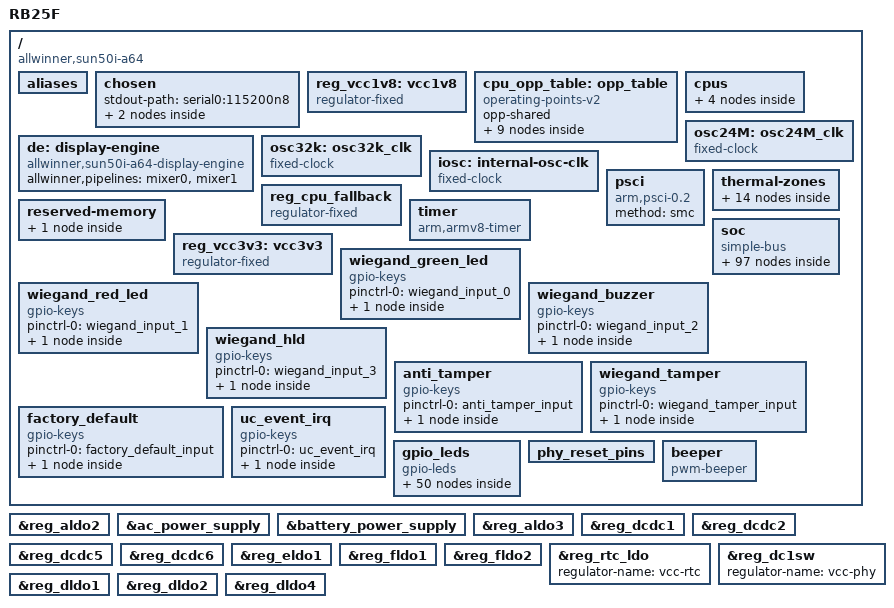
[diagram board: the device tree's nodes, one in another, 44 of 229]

/dts-v1/;

#include <dt-bindings/clock/sun8i-de2.h>
#include <dt-bindings/clock/sun50i-a64-ccu.h>
#include <dt-bindings/clock/sun8i-r-ccu.h>
#include <dt-bindings/interrupt-controller/arm-gic.h>
#include <dt-bindings/reset/sun8i-de2.h>
#include <dt-bindings/reset/sun50i-a64-ccu.h>
#include <dt-bindings/clock/sun8i-de2.h>
#include <dt-bindings/reset/sun8i-de2.h>
#include <dt-bindings/clock/sun8i-r-ccu.h>
#include <dt-bindings/reset/sun8i-r-ccu.h>
#include <dt-bindings/thermal/thermal.h>
#include <dt-bindings/gpio/gpio.h>

/ {
	model = "RB25F";
	compatible = "allwinner,sun50i-a64";
	interrupt-parent = <&gic>;
	#address-cells = <1>;
	#size-cells = <1>;

	aliases {
		serial0 = &uart0;
		ethernet0 = &emac;
		serial3 = "/soc/serial@1c28c00";
		serial2 = "/soc/serial@1c28800";
		i2c1 = "/soc/i2c@1c2b000";
	};

	chosen {
		stdout-path = "serial0:115200n8";
		#address-cells = <1>;
		#size-cells = <1>;
		ranges;

		simplefb_lcd: framebuffer-lcd {
			compatible = "allwinner,simple-framebuffer",
				     "simple-framebuffer";
			allwinner,pipeline = "mixer0-lcd0";
			clocks = <&display_clocks CLK_BUS_MIXER0>,
				 <&ccu CLK_BUS_TCON0>, <&ccu CLK_BUS_TCON0>,
				 <&display_clocks CLK_MIXER0>,
				 <&ccu CLK_TCON0>;
			status = "disabled";
		};

		simplefb_hdmi: framebuffer-hdmi {
			compatible = "allwinner,simple-framebuffer",
				     "simple-framebuffer";
			allwinner,pipeline = "mixer1-lcd1-hdmi";
			clocks = <&display_clocks CLK_BUS_MIXER1>,
				 <&ccu CLK_BUS_TCON1>, <&ccu CLK_BUS_HDMI>,
				 <&display_clocks CLK_MIXER1>,
				 <&ccu CLK_TCON1>, <&ccu CLK_HDMI>,
				 <&ccu CLK_HDMI_DDC>;
			status = "disabled";
		};
	};

	reg_vcc1v8: vcc1v8 {
		compatible = "regulator-fixed";
		regulator-name = "vcc1v8";
		regulator-min-microvolt = <1800000>;
		regulator-max-microvolt = <1800000>;
	};

	cpu_opp_table: opp_table {
		compatible = "operating-points-v2";
		opp-shared;

		opp@408000000 {
			opp-hz = /bits/ 64 <408000000>;
			opp-microvolt = <1000000 1000000 1300000>;
			clock-latency-ns = <244144>; /* 8 32k periods */
		};

		opp@648000000 {
			opp-hz = /bits/ 64 <648000000>;
			opp-microvolt = <1040000 1040000 1300000>;
			clock-latency-ns = <244144>; /* 8 32k periods */
		};

		opp@816000000 {
			opp-hz = /bits/ 64 <816000000>;
			opp-microvolt = <1080000 1080000 1300000>;
			clock-latency-ns = <244144>; /* 8 32k periods */
		};

		opp@912000000 {
		       opp-hz = /bits/ 64 <912000000>;
		       opp-microvolt = <1120000 1120000 1300000>;
		       clock-latency-ns = <244144>; /* 8 32k periods */
		};

		opp@960000000 {
		       opp-hz = /bits/ 64 <960000000>;
		       opp-microvolt = <1160000 1160000 1300000>;
		       clock-latency-ns = <244144>; /* 8 32k periods */
		};

		opp@1008000000 {
		       opp-hz = /bits/ 64 <1008000000>;
		       opp-microvolt = <1200000 1200000 1300000>;
		       clock-latency-ns = <244144>; /* 8 32k periods */
		};

		opp@1056000000 {
		       opp-hz = /bits/ 64 <1056000000>;
		       opp-microvolt = <1240000 1240000 1300000>;
		       clock-latency-ns = <244144>; /* 8 32k periods */
		};

		opp@1104000000 {
		       opp-hz = /bits/ 64 <1104000000>;
		       opp-microvolt = <1260000 1260000 1300000>;
		       clock-latency-ns = <244144>; /* 8 32k periods */
		};

		opp@1152000000 {
		       opp-hz = /bits/ 64 <1152000000>;
		       opp-microvolt = <1300000 1300000 1300000>;
		       clock-latency-ns = <244144>; /* 8 32k periods */
		};
	};

	cpus {
		#address-cells = <1>;
		#size-cells = <0>;

		cpu0: cpu@0 {
			compatible = "arm,cortex-a53", "arm,armv8";
			device_type = "cpu";
			reg = <0>;
			enable-method = "psci";
			operating-points-v2 = <&cpu_opp_table>;
			cpu-supply = <&reg_cpu_fallback>;
			#cooling-cells = <2>;
		};

		cpu1: cpu@1 {
			compatible = "arm,cortex-a53", "arm,armv8";
			device_type = "cpu";
			reg = <1>;
			enable-method = "psci";
			operating-points-v2 = <&cpu_opp_table>;
		};

		cpu2: cpu@2 {
			compatible = "arm,cortex-a53", "arm,armv8";
			device_type = "cpu";
			reg = <2>;
			enable-method = "psci";
			operating-points-v2 = <&cpu_opp_table>;
		};

		cpu3: cpu@3 {
			compatible = "arm,cortex-a53", "arm,armv8";
			device_type = "cpu";
			reg = <3>;
			enable-method = "psci";
			operating-points-v2 = <&cpu_opp_table>;
		};
	};

	de: display-engine {
		compatible = "allwinner,sun50i-a64-display-engine";
		allwinner,pipelines = <&mixer0>,
				      <&mixer1>;
		status = "disabled";
	};

	osc24M: osc24M_clk {
		#clock-cells = <0>;
		compatible = "fixed-clock";
		clock-frequency = <24000000>;
		clock-output-names = "osc24M";
	};

	osc32k: osc32k_clk {
		#clock-cells = <0>;
		compatible = "fixed-clock";
		clock-frequency = <32768>;
		clock-output-names = "osc32k";
	};

	iosc: internal-osc-clk {
		#clock-cells = <0>;
		compatible = "fixed-clock";
		clock-frequency = <16000000>;
		clock-accuracy = <300000000>;
		clock-output-names = "iosc";
	};

	psci {
		compatible = "arm,psci-0.2";
		method = "smc";
	};

	thermal-zones {
		cpu-thermal {
			/* milliseconds */
			polling-delay-passive = <250>;
			polling-delay = <1000>;
			thermal-sensors = <&ths>;

			trips {
				cpu_warm: cpu_warm {
					temperature = <65000>;
					hysteresis = <2000>;
					type = "passive";
				};

				cpu_hot_pre: cpu_hot_pre {
					temperature = <70000>;
					hysteresis = <2000>;
					type = "passive";
				};

				cpu_hot: cpu_hot {
					temperature = <75000>;
					hysteresis = <2000>;
					type = "passive";
				};

				cpu_very_hot_pre: cpu_very_hot_pre {
					temperature = <85000>;
					hysteresis = <2000>;
					type = "passive";
				};

				cpu_very_hot: cpu_very_hot {
					temperature = <90000>;
					hysteresis = <2000>;
					type = "passive";
				};

				cpu_crit: cpu_crit {
					temperature = <105000>;
					hysteresis = <2000>;
					type = "critical";
				};
			};

			cooling-maps {
				cpu_warm_limit_cpu {
					trip = <&cpu_warm>;
					cooling-device = <&cpu0 THERMAL_NO_LIMIT 2>;
				};

				cpu_hot_pre_limit_cpu {
					trip = <&cpu_hot_pre>;
					cooling-device = <&cpu0 2 3>;
				};

				cpu_hot_limit_cpu {
					trip = <&cpu_hot>;
					cooling-device = <&cpu0 3 4>;
				};

				cpu_very_hot_pre_limit_cpu {
					trip = <&cpu_very_hot>;
					cooling-device = <&cpu0 5 6>;
				};

				cpu_very_hot_limit_cpu {
					trip = <&cpu_very_hot>;
					cooling-device = <&cpu0 7 THERMAL_NO_LIMIT>;
				};
			};
		};
	};

	reg_cpu_fallback: reg_cpu_fallback  {
		compatible = "regulator-fixed";
		regulator-name = "vdd-cpux-dummy";
		regulator-min-microvolt = <1100000>;
		regulator-max-microvolt = <1100000>;
	};

	reserved-memory {
		#address-cells = <1>;
		#size-cells = <1>;
		ranges;

		cma: linux,cma {
			compatible = "shared-dma-pool";
			reusable;
			size = <0x4000000>;
			alignment = <0x2000>;
			linux,cma-default;
		};
	};
	
	timer {
		compatible = "arm,armv8-timer";
		fsl,erratum-a008585;
		interrupts = <GIC_PPI 13
			(GIC_CPU_MASK_SIMPLE(4) | IRQ_TYPE_LEVEL_HIGH)>,
			     <GIC_PPI 14
			(GIC_CPU_MASK_SIMPLE(4) | IRQ_TYPE_LEVEL_HIGH)>,
			     <GIC_PPI 11
			(GIC_CPU_MASK_SIMPLE(4) | IRQ_TYPE_LEVEL_HIGH)>,
			     <GIC_PPI 10
			(GIC_CPU_MASK_SIMPLE(4) | IRQ_TYPE_LEVEL_HIGH)>;
	};

	soc {
		compatible = "simple-bus";
		#address-cells = <1>;
		#size-cells = <1>;
		ranges;

		ths: thermal-sensor@1c25000 {
			compatible = "allwinner,sun50i-h5-ths";
			reg = <0x01c25000 0x100>;
			clocks = <&ccu CLK_BUS_THS>, <&ccu CLK_THS>;
			clock-names = "bus", "mod";
			resets = <&ccu RST_BUS_THS>;
			#thermal-sensor-cells = <0>;
			#io-channel-cells = <0>;
		};

		display_clocks: clock@1000000 {
			compatible = "allwinner,sun50i-a64-de2-clk";
			reg = <0x01000000 0x100000>;
			clocks = <&ccu CLK_DE>,
				 <&ccu CLK_BUS_DE>;
			clock-names = "mod",
				      "bus";
			resets = <&ccu RST_BUS_DE>;
			allwinner,sram = <&de2_sram 1>;
			#clock-cells = <1>;
			#reset-cells = <1>;
		};

		mixer0: mixer@1100000 {
			compatible = "allwinner,sun50i-a64-de2-mixer0";
			reg = <0x01100000 0x100000>;
			clocks = <&display_clocks CLK_MIXER0>,
				 <&display_clocks CLK_BUS_MIXER0>;
			clock-names = "mod",
				      "bus";
			resets = <&display_clocks RST_MIXER0>;
			status = "disabled";

			ports {
				#address-cells = <1>;
				#size-cells = <0>;

				mixer0_out: port@1 {
					#address-cells = <1>;
					#size-cells = <0>;
					reg = <1>;

					mixer0_out_tcon0: endpoint@0 {
						reg = <0>;
						remote-endpoint = <&tcon0_in_mixer0>;
					};

					mixer0_out_tcon1: endpoint@1 {
						reg = <1>;
						remote-endpoint = <&tcon1_in_mixer0>;
					};
				};
			};
		};

		mixer1: mixer@1200000 {
			compatible = "allwinner,sun50i-a64-de2-mixer1";
			reg = <0x01200000 0x100000>;
			clocks = <&display_clocks CLK_MIXER1>,
				 <&display_clocks CLK_BUS_MIXER1>;
			clock-names = "mod",
				      "bus";
			resets = <&display_clocks RST_MIXER1>;
			status = "disabled";

			ports {
				#address-cells = <1>;
				#size-cells = <0>;

				mixer1_out: port@1 {
					#address-cells = <1>;
					#size-cells = <0>;
					reg = <1>;

					mixer1_out_tcon1: endpoint@0 {
						reg = <0>;
						remote-endpoint = <&tcon1_in_mixer1>;
					};

					mixer1_out_tcon0: endpoint@1 {
						reg = <1>;
						remote-endpoint = <&tcon0_in_mixer1>;
					};
				};
			};
		};

		tcon0: lcd-controller@01c0c000 {
			compatible = "allwinner,sun50i-a64-tcon0";
			reg = <0x01c0c000 0x1000>;
			interrupts = <GIC_SPI 86 IRQ_TYPE_LEVEL_HIGH>;
			clocks = <&ccu CLK_BUS_TCON0>,
				 <&ccu CLK_TCON0>;
			clock-names = "ahb",
				      "tcon-ch0";
			clock-output-names = "tcon-pixel-clock";
			resets = <&ccu RST_BUS_TCON0>;
			reset-names = "lcd";
			status = "disabled";

			ports {
				#address-cells = <1>;
				#size-cells = <0>;

				tcon0_in: port@0 {
					#address-cells = <1>;
					#size-cells = <0>;
					reg = <0>;

					tcon0_in_mixer0: endpoint@0 {
						reg = <0>;
						remote-endpoint = <&mixer0_out_tcon0>;
					};

					tcon0_in_mixer1: endpoint@1 {
						reg = <1>;
						remote-endpoint = <&mixer1_out_tcon0>;
					};
				};

				tcon0_out: port@1 {
					#address-cells = <1>;
					#size-cells = <0>;
					reg = <1>;
				};
			};
		};

		tcon1: lcd-controller@1c0d000 {
			compatible = "allwinner,sun50i-a64-tcon1";
			reg = <0x01c0d000 0x1000>;
			interrupts = <GIC_SPI 87 IRQ_TYPE_LEVEL_HIGH>;
			clocks = <&ccu CLK_BUS_TCON1>,
				 <&ccu CLK_TCON1>;
			clock-names = "ahb",
				      "tcon-ch1";
			resets = <&ccu RST_BUS_TCON1>;
			reset-names = "lcd";
			status = "disabled";

			ports {
				#address-cells = <1>;
				#size-cells = <0>;

				tcon1_in: port@0 {
					#address-cells = <1>;
					#size-cells = <0>;
					reg = <0>;

					tcon1_in_mixer1: endpoint@0 {
						reg = <0>;
						remote-endpoint = <&mixer1_out_tcon1>;
					};

					tcon1_in_mixer0: endpoint@1 {
						reg = <1>;
						remote-endpoint = <&mixer0_out_tcon1>;
					};
				};

				tcon1_out: port@1 {
					#address-cells = <1>;
					#size-cells = <0>;
					reg = <1>;

					tcon1_out_hdmi: endpoint@1 {
						reg = <1>;
						remote-endpoint = <&hdmi_in_tcon1>;
					};
				};
			};
		};

		syscon: syscon@1c00000 {
			compatible = "allwinner,sun50i-a64-system-controller",
				"syscon";
			reg = <0x01c00000 0x1000>;
		};

		dma: dma-controller@1c02000 {
			compatible = "allwinner,sun50i-a64-dma";
			reg = <0x01c02000 0x1000>;
			interrupts = <GIC_SPI 50 IRQ_TYPE_LEVEL_HIGH>;
			clocks = <&ccu CLK_BUS_DMA>;
			dma-channels = <8>;
			dma-requests = <27>;
			resets = <&ccu RST_BUS_DMA>;
			#dma-cells = <1>;
		};

		sram-controller@1c00000 {
			compatible = "allwinner,sun50i-a64-sram-controller";
			reg = <0x01c00000 0x1000>;
			#address-cells = <1>;
			#size-cells = <1>;
			ranges;

			sram_c: sram@18000 {
				compatible = "mmio-sram";
				reg = <0x00018000 0x28000>;
				#address-cells = <1>;
				#size-cells = <1>;
				ranges = <0 0x00018000 0x28000>;

				de2_sram: sram-section@0 {
					compatible = "allwinner,sun50i-a64-sram-c";
					reg = <0x0000 0x28000>;
				};
			};
		};

		mmc0: mmc@1c0f000 {
			compatible = "allwinner,sun50i-a64-mmc";
			reg = <0x01c0f000 0x1000>;
			clocks = <&ccu CLK_BUS_MMC0>, <&ccu CLK_MMC0>;
			clock-names = "ahb", "mmc";
			resets = <&ccu RST_BUS_MMC0>;
			reset-names = "ahb";
			interrupts = <GIC_SPI 60 IRQ_TYPE_LEVEL_HIGH>;
			max-frequency = <150000000>;
			status = "disabled";
			#address-cells = <1>;
			#size-cells = <0>;
		};

		mmc2: mmc@1c11000 {
			compatible = "allwinner,sun50i-a64-emmc";
			reg = <0x01c11000 0x1000>;
			clocks = <&ccu CLK_BUS_MMC2>, <&ccu CLK_MMC2>;
			clock-names = "ahb", "mmc";
			resets = <&ccu RST_BUS_MMC2>;
			reset-names = "ahb";
			interrupts = <GIC_SPI 62 IRQ_TYPE_LEVEL_HIGH>;
			max-frequency = <200000000>;
			status = "disabled";
			#address-cells = <1>;
			#size-cells = <0>;
		};

		usb_otg: usb@01c19000 {
			compatible = "allwinner,sun8i-a33-musb";
			reg = <0x01c19000 0x0400>;
			clocks = <&ccu CLK_BUS_OTG>;
			resets = <&ccu RST_BUS_OTG>;
			interrupts = <GIC_SPI 71 IRQ_TYPE_LEVEL_HIGH>;
			interrupt-names = "mc";
			phys = <&usbphy 0>;
			phy-names = "usb";
			extcon = <&usbphy 0>;
			status = "disabled";
		};

		usbphy: phy@01c19400 {
			compatible = "allwinner,sun50i-a64-usb-phy";
			reg = <0x01c19400 0x14>,
			      <0x01c1a800 0x4>,
			      <0x01c1b800 0x4>;
			reg-names = "phy_ctrl",
				    "pmu0",
				    "pmu1";
			clocks = <&ccu CLK_USB_PHY0>,
				 <&ccu CLK_USB_PHY1>;
			clock-names = "usb0_phy",
				      "usb1_phy";
			resets = <&ccu RST_USB_PHY0>,
				 <&ccu RST_USB_PHY1>;
			reset-names = "usb0_reset",
				      "usb1_reset";
			status = "disabled";
			#phy-cells = <1>;
		};

		ehci0: usb@01c1a000 {
			compatible = "allwinner,sun50i-a64-ehci", "generic-ehci";
			reg = <0x01c1a000 0x100>;
			interrupts = <GIC_SPI 72 IRQ_TYPE_LEVEL_HIGH>;
			clocks = <&ccu CLK_BUS_OHCI0>,
				 <&ccu CLK_BUS_EHCI0>,
				 <&ccu CLK_USB_OHCI0>;
			resets = <&ccu RST_BUS_OHCI0>,
				 <&ccu RST_BUS_EHCI0>;
			status = "disabled";
		};

		ohci0: usb@01c1a400 {
			compatible = "allwinner,sun50i-a64-ohci", "generic-ohci";
			reg = <0x01c1a400 0x100>;
			interrupts = <GIC_SPI 73 IRQ_TYPE_LEVEL_HIGH>;
			clocks = <&ccu CLK_BUS_OHCI0>,
				 <&ccu CLK_USB_OHCI0>;
			resets = <&ccu RST_BUS_OHCI0>;
			status = "disabled";
		};

		ehci1: usb@01c1b000 {
			compatible = "allwinner,sun50i-a64-ehci", "generic-ehci";
			reg = <0x01c1b000 0x100>;
			interrupts = <GIC_SPI 74 IRQ_TYPE_LEVEL_HIGH>;
			clocks = <&ccu CLK_BUS_OHCI1>,
				 <&ccu CLK_BUS_EHCI1>,
				 <&ccu CLK_USB_OHCI1>;
			resets = <&ccu RST_BUS_OHCI1>,
				 <&ccu RST_BUS_EHCI1>;
			phys = <&usbphy 1>;
			phy-names = "usb";
			status = "disabled";
		};

		ohci1: usb@01c1b400 {
			compatible = "allwinner,sun50i-a64-ohci", "generic-ohci";
			reg = <0x01c1b400 0x100>;
			interrupts = <GIC_SPI 75 IRQ_TYPE_LEVEL_HIGH>;
			clocks = <&ccu CLK_BUS_OHCI1>,
				 <&ccu CLK_USB_OHCI1>;
			resets = <&ccu RST_BUS_OHCI1>;
			phys = <&usbphy 1>;
			phy-names = "usb";
			status = "disabled";
		};

		ccu: clock@01c20000 {
			compatible = "allwinner,sun50i-a64-ccu";
			reg = <0x01c20000 0x400>;
			clocks = <&osc24M>, <&osc32k>;
			clock-names = "hosc", "losc";
			#clock-cells = <1>;
			#reset-cells = <1>;
		};

		pio: pinctrl@1c20800 {
			compatible = "allwinner,sun50i-a64-pinctrl";
			reg = <0x01c20800 0x400>;
			interrupts = <GIC_SPI 11 IRQ_TYPE_LEVEL_HIGH>,
				     <GIC_SPI 17 IRQ_TYPE_LEVEL_HIGH>,
				     <GIC_SPI 21 IRQ_TYPE_LEVEL_HIGH>;
			clocks = <&ccu 58>;
			gpio-controller;
			#gpio-cells = <3>;
			interrupt-controller;
			#interrupt-cells = <3>;

			/* 
			* pcf8563 connections
			* Pi2 pin  Sig     Pcf pin
			*  1       +3V3    8
			*  3       SDA     5
			*  5       SCL     6
			*  9       GND     4
			*/
			i2c1_pins: i2c1_pins {
				pins = "PH2", "PH3";
				function = "i2c1";
			};

			lcd_rgb666_pins: lcd-rgb666 {
				pins = "PD0", "PD1", "PD2", "PD3", "PD4",
				       "PD5", "PD6", "PD7", "PD8", "PD9",
				       "PD10", "PD11", "PD12", "PD13",
				       "PD14", "PD15", "PD16", "PD17",
				       "PD18", "PD19", "PD20", "PD21";
				function = "lcd0";
			};

			mmc0_pins: mmc0-pins {
				pins = "PF0", "PF1", "PF2", "PF3",
				       "PF4", "PF5";
				function = "mmc0";
				drive-strength = <30>;
				bias-pull-up;
			};

			mmc2_pins: mmc2-pins {
				pins = "PC1", "PC5", "PC6", "PC8", "PC9",
				       "PC10","PC11", "PC12", "PC13",
				       "PC14", "PC15", "PC16";
				function = "mmc2";
				drive-strength = <30>;
				bias-pull-up;
			};

			/*Ethernet*/
			rmii_pins: rmii_pins {
				pins = "PD10", "PD11", "PD13", "PD14", "PD17",
				       "PD18", "PD19", "PD20", "PD22", "PD23";
				function = "emac";
				drive-strength = <40>;
			};

/*			rgmii_pins: rgmii_pins {
				pins = "PD8", "PD9", "PD10", "PD11", "PD12",
				       "PD13", "PD15", "PD16", "PD17", "PD18",
				       "PD19", "PD20", "PD21", "PD22", "PD23";
				function = "emac";
				drive-strength = <40>;
			};*/

			/*
			spi0_pins: spi0 {
				pins = "PC0", "PC1", "PC2", "PC3";
				function = "spi0";
			};*/

			spi1_pins: spi1 {
				pins = "PA15", "PA16", "PA14", "PA13";
				function = "spi1";
			};

			uart0_pins_a: uart0@0 {
				pins = "PB8", "PB9";
				function = "uart0";
			};

			uart1_pins: uart1_pins {
				pins = "PG6", "PG7";
				function = "uart1";
			};

/*			uart1_rts_cts_pins: uart1_rts_cts_pins {
				pins = "PG8", "PG9";
				function = "uart1";
			};*/

			uart2_pins: uart2-pins {
				pins = "PB0", "PB1";
				function = "uart2";
			};

			uart2_rts_cts_pins: uart2_rts_cts_pins {
				pins = "PB2", "PB3";
				function = "uart2";
			};

			uart3_pins: uart3-pins {
				pins = "PH4", "PH5";
				function = "uart3";
			};

			uart4_pins: uart4-pins {
				pins = "PD2", "PD3";
				function = "uart4";
			};

/*			uart4_rts_cts_pins: uart4-rts-cts-pins {
				pins = "PD4", "PD5";
				function = "uart4";
			};*/
			
			wiegand_input_0: wiegand_input_0 {
				pins = "PG2";
				function = "gpio_in";
				debounce-interval = <40>;
			};
	
			wiegand_input_1: wiegand_input_1 {
				pins = "PG3";
				function = "gpio_in";
				debounce-interval = <40>;
			};
	
			wiegand_input_2: wiegand_input_2 {
				pins = "PG4";
				function = "gpio_in";
				debounce-interval = <40>;
			};

			wiegand_input_3: wiegand_input_3 {
				pins = "PG5";
				function = "gpio_in";
				debounce-interval = <40>;
			};
			
			anti_tamper_input: anti_tamper_input {
				pins = "PH9";
				function = "gpio_in";
				debounce-interval = <40>;
			};			
			
			wiegand_tamper_input: wiegand_tamper_input {
				pins = "PH0";
				function = "gpio_in";
				debounce-interval = <40>;
			};
			
			factory_default_input: factory_default_input {
			  pins = "PH6";
			  function = "gpio_in";
			  debounce-interval = <40>;
			};
			
			uc_event_irq: uc_event_irq_input {
			  pins = "PB3";
			  function = "gpio_in";
			  bias-pull-up;
			  debounce-interval = <40>;
			};
			
		};

		pwm: pwm@01c21400 {
			compatible = "allwinner,sun50i-a64-pwm";
			reg = <0x01c21400 0x8>;
			clocks = <&osc24M>;
			#pwm-cells = <3>;
			status = "okay";
		};

		r_pwm: r_pwm@01f03800 {
			compatible = "allwinner,sun50i-a64-pwm",
									 "allwinner,sun5i-a13-pwm";
			reg = <0x01f03800 0x400>;
			clocks = <&osc24M>;
			#pwm-cells = <3>;
			status = "okay";
		};
		
		/*
		spi0: spi@01c68000 {
			compatible = "allwinner,sun8i-h3-spi";
			reg = <0x01c68000 0x1000>;
			interrupts = <GIC_SPI 65 IRQ_TYPE_LEVEL_HIGH>;
			clocks = <&ccu CLK_BUS_SPI0>, <&ccu CLK_SPI0>;
			clock-names = "ahb", "mod";
			pinctrl-names = "default";
			pinctrl-0 = <&spi0_pins>;
			resets = <&ccu RST_BUS_SPI0>;
			status = "disabled";
			#address-cells = <1>;
			#size-cells = <0>;
		};*/

		spi1: spi@01c69000 {
			compatible = "allwinner,sun8i-h3-spi";
			reg = <0x01c69000 0x1000>;
			interrupts = <GIC_SPI 66 IRQ_TYPE_LEVEL_HIGH>;
			clocks = <&ccu CLK_BUS_SPI1>, <&ccu CLK_SPI1>;
			clock-names = "ahb", "mod";
			pinctrl-names = "default";
			pinctrl-0 = <&spi1_pins>;
			resets = <&ccu RST_BUS_SPI1>;
			status = "disabled";
			#address-cells = <1>;
			#size-cells = <0>;
		};

		uart0: serial@1c28000 {
			compatible = "snps,dw-apb-uart";
			reg = <0x01c28000 0x400>;
			interrupts = <GIC_SPI 0 IRQ_TYPE_LEVEL_HIGH>;
			reg-shift = <2>;
			reg-io-width = <4>;
			clocks = <&ccu CLK_BUS_UART0>;
			resets = <&ccu RST_BUS_UART0>;
			status = "disabled";
		};

		uart1: serial@1c28400 {
			compatible = "snps,dw-apb-uart";
			reg = <0x01c28400 0x400>;
			interrupts = <GIC_SPI 1 IRQ_TYPE_LEVEL_HIGH>;
			reg-shift = <2>;
			reg-io-width = <4>;
			clocks = <&ccu CLK_BUS_UART1>;
			resets = <&ccu RST_BUS_UART1>;
			pinctrl-names = "default";
			pinctrl-0 = <&uart1_pins>;			
			status = "okay";
		};

		uart2: serial@1c28800 {
			compatible = "snps,dw-apb-uart";
			reg = <0x01c28800 0x400>;
			interrupts = <GIC_SPI 2 IRQ_TYPE_LEVEL_HIGH>;
			reg-shift = <2>;
			reg-io-width = <4>;
			clocks = <&ccu CLK_BUS_UART2>;
			resets = <&ccu RST_BUS_UART2>;
			pinctrl-names = "default";
			pinctrl-0 = <&uart2_pins>;
			status = "okay";
		};

		uart3: serial@1c28c00 {
			compatible = "snps,dw-apb-uart";
			reg = <0x01c28c00 0x400>;
			interrupts = <GIC_SPI 3 IRQ_TYPE_LEVEL_HIGH>;
			reg-shift = <2>;
			reg-io-width = <4>;
			clocks = <&ccu CLK_BUS_UART3>;
			resets = <&ccu RST_BUS_UART3>;
			pinctrl-names = "default";
			pinctrl-0 = <&uart3_pins>;
			status = "okay";
		};

		uart4: serial@1c29000 {
			compatible = "snps,dw-apb-uart";
			reg = <0x01c29000 0x400>;
			interrupts = <GIC_SPI 4 IRQ_TYPE_LEVEL_HIGH>;
			reg-shift = <2>;
			reg-io-width = <4>;
			clocks = <&ccu CLK_BUS_UART4>;
			resets = <&ccu RST_BUS_UART4>;
			status = "disabled";
		};

		i2c0: i2c@1c2ac00 {
			compatible = "allwinner,sun6i-a31-i2c";
			reg = <0x01c2ac00 0x400>;
			interrupts = <GIC_SPI 6 IRQ_TYPE_LEVEL_HIGH>;
			clocks = <&ccu CLK_BUS_I2C0>;
			resets = <&ccu RST_BUS_I2C0>;
			status = "disabled";
			#address-cells = <1>;
			#size-cells = <0>;
		};
		
		/* Create new rtc via i2c1 */
		i2c1: i2c@1c2b000 {
			compatible = "allwinner,sun6i-a31-i2c";
			reg = <0x01c2b000 0x400>;
			interrupts = <GIC_SPI 7 IRQ_TYPE_LEVEL_HIGH>;
			clocks = <&ccu CLK_BUS_I2C1>;
			resets = <&ccu RST_BUS_I2C1>;
			#address-cells = <1>;
			#size-cells = <0>;
			pinctrl-names = "default";
			pinctrl-0 = <&i2c1_pins>;
			status = "okay";
			
			/* Requires the following to be added in "/boot/armbianEnv.txt"
			 * overlay_prefix=sun50i-a64
			 * overlays=i2c1
			 * user_overlays=pcf8563
			 *
			 * Place a compiled version of this file in "/boot/user_overlays"
			 *
			 * Remove and disable the fake hardware clock
			 * apt-get purge fake-hwclock
			 * update-rc.d -f fake-hwclock remove
			 *
			 * A force read via "/etc/rc.local" is required to initially set the 
			 * system clock from the rtc at boot.
			 * hwclock --hctosys -f /dev/rtc0
			 *
			 * For some reason, ntp can interfere with reading the rtc at boot, causing 
			 * the rtc to be written to prior to setting the system clock.
			 * disable auto starting of ntp "update-rc.d -f ntp remove"
			 * however you can start ntp manually in "/etc/rc.local" after setting the system clock
			 * with "service ntp start"
			 */
			pcf8563@51 {
				compatible = "nxp,pcf8563";
				reg = <0x51>;
				clock-frequency = <400000>;
				status = "okay";
			};
		};

		i2c2: i2c@1c2b400 {
			compatible = "allwinner,sun6i-a31-i2c";
			reg = <0x01c2b400 0x400>;
			interrupts = <GIC_SPI 8 IRQ_TYPE_LEVEL_HIGH>;
			clocks = <&ccu CLK_BUS_I2C2>;
			resets = <&ccu RST_BUS_I2C2>;
			status = "disabled";
			#address-cells = <1>;
			#size-cells = <0>;
		};

		emac: ethernet@1c30000 {
			compatible = "allwinner,sun50i-a64-emac";
			syscon = <&syscon>;
			reg = <0x01c30000 0x10000>;
			interrupts = <GIC_SPI 82 IRQ_TYPE_LEVEL_HIGH>;
			interrupt-names = "macirq";
			resets = <&ccu RST_BUS_EMAC>;
			reset-names = "stmmaceth";
			clocks = <&ccu CLK_BUS_EMAC>;
			clock-names = "stmmaceth";
			status = "disabled";
			#address-cells = <1>;
			#size-cells = <0>;

			mdio: mdio {
				compatible = "snps,dwmac-mdio";				
				#address-cells = <1>;
				#size-cells = <0>;
			};

			mdio-mux {
				compatible = "allwinner,sun8i-h3-mdio-mux";
				#address-cells = <1>;
				#size-cells = <0>;

				mdio-parent-bus = <&mdio>;
				/* Only one MDIO is usable at the time */
				internal_mdio: mdio@1 {
					compatible = "allwinner,sun50i-a64-emac";
 					reg = <1>;
					#address-cells = <1>;
					#size-cells = <0>;

					int_mii_phy: ethernet-phy@1 {
						compatible = "ethernet-phy-ieee802.3-c22";
						reg = <1>;
						clocks = <&ccu CLK_BUS_EMAC>;
						resets = <&ccu RST_BUS_EMAC>;
					};
				};

				external_mdio: mdio@2 {
					reg = <2>;
					#address-cells = <1>;
					#size-cells = <0>;
 				};
 			};
		};

		mali: gpu@1c40000 {
			compatible = "allwinner,sun50i-a64-mali",
				     "allwinner,sun7i-a20-mali", "arm,mali-400";
			reg = <0x01c40000 0x10000>;
			interrupts = <GIC_SPI 97 IRQ_TYPE_LEVEL_HIGH>,
				     <GIC_SPI 98 IRQ_TYPE_LEVEL_HIGH>,
				     <GIC_SPI 99 IRQ_TYPE_LEVEL_HIGH>,
				     <GIC_SPI 100 IRQ_TYPE_LEVEL_HIGH>,
				     <GIC_SPI 102 IRQ_TYPE_LEVEL_HIGH>,
				     <GIC_SPI 103 IRQ_TYPE_LEVEL_HIGH>,
				     <GIC_SPI 101 IRQ_TYPE_LEVEL_HIGH>;
			interrupt-names = "gp",
					  "gpmmu",
					  "pp0",
					  "ppmmu0",
					  "pp1",
					  "ppmmu1",
					  "pmu";
			clocks = <&ccu CLK_BUS_GPU>, <&ccu CLK_GPU>;
			clock-names = "bus", "core";
			resets = <&ccu RST_BUS_GPU>;
			memory-region = <&cma>;

			assigned-clocks = <&ccu CLK_GPU>;
			assigned-clock-rates = <384000000>;
		};

		gic: interrupt-controller@1c81000 {
			compatible = "arm,gic-400";
			reg = <0x01c81000 0x1000>,
			      <0x01c82000 0x2000>,
			      <0x01c84000 0x2000>,
			      <0x01c86000 0x2000>;
			interrupts = <GIC_PPI 9 (GIC_CPU_MASK_SIMPLE(4) | IRQ_TYPE_LEVEL_HIGH)>;
			interrupt-controller;
			#interrupt-cells = <3>;
		};

		hdmi: hdmi@1ee0000 {
			compatible = "allwinner,h3-dw-hdmi";
			reg = <0x01ee0000 0x10000>,
			      <0x01ef0000 0x10000>;
			reg-io-width = <1>;
			interrupts = <GIC_SPI 88 IRQ_TYPE_LEVEL_HIGH>;
			clocks = <&ccu CLK_BUS_HDMI>, <&ccu CLK_HDMI>,
				 <&ccu CLK_HDMI_DDC>;
			clock-names = "iahb", "isfr", "iddc";
			resets = <&ccu RST_BUS_HDMI0>, <&ccu RST_BUS_HDMI1>;
			reset-names = "hdmi", "ddc";
			status = "disabled";

			ports {
				#address-cells = <1>;
				#size-cells = <0>;

				port@0 {
					reg = <0>;
					#address-cells = <1>;
					#size-cells = <0>;

					hdmi_in_tcon1: endpoint@0 {
						reg = <0>;
						remote-endpoint = <&tcon1_out_hdmi>;
					};
				};
			};
		};

		/* Removing native RTC i.o.t. use the pcf8563 on i2c */
		rtc: rtc@1f00000 {
			compatible = "allwinner,sun6i-a31-rtc";
			reg = <0x01f00000 0x54>;
			interrupts = <GIC_SPI 40 IRQ_TYPE_LEVEL_HIGH>,
				     	 <GIC_SPI 41 IRQ_TYPE_LEVEL_HIGH>;
			/* Disable the existing onboard rtc for pcf8563 to work*/
			status = "disabled";
		};

		r_intc: interrupt-controller@1f00c00 {
			compatible = "allwinner,sun50i-a64-r-intc",
				     "allwinner,sun6i-a31-r-intc";
			interrupt-controller;
			#interrupt-cells = <2>;
			reg = <0x01f00c00 0x400>;
			interrupts = <GIC_SPI 32 IRQ_TYPE_LEVEL_HIGH>;
		};

		nmi_intc: interrupt-controller@01f00c0c {
			compatible = "allwinner,sun6i-a31-sc-nmi";
			interrupt-controller;
			#interrupt-cells = <2>;
			reg = <0x01f00c0c 0x38>;
			interrupts = <GIC_SPI 32 IRQ_TYPE_LEVEL_HIGH>;
		};

		r_ccu: clock@1f01400 {
			compatible = "allwinner,sun50i-a64-r-ccu";
			reg = <0x01f01400 0x100>;
			clocks = <&osc24M>, <&osc32k>, <&iosc>,
				 <&ccu 11>;
			clock-names = "hosc", "losc", "iosc", "pll-periph";
			#clock-cells = <1>;
			#reset-cells = <1>;
		};

		r_i2c: i2c@1f02400 {
			compatible = "allwinner,sun6i-a31-i2c";
			reg = <0x01f02400 0x400>;
			interrupts = <GIC_SPI 44 IRQ_TYPE_LEVEL_HIGH>;
			clocks = <&r_ccu CLK_APB0_I2C>;
			resets = <&r_ccu RST_APB0_I2C>;
			status = "disabled";
			#address-cells = <1>;
			#size-cells = <0>;
		};

		r_pio: pinctrl@01f02c00 {
			compatible = "allwinner,sun50i-a64-r-pinctrl";
			reg = <0x01f02c00 0x400>;
			interrupts = <GIC_SPI 45 IRQ_TYPE_LEVEL_HIGH>;
			clocks = <&r_ccu CLK_APB0_PIO>, <&osc24M>, <&osc32k>;
			clock-names = "apb", "hosc", "losc";
			gpio-controller;
			#gpio-cells = <3>;
			interrupt-controller;
			#interrupt-cells = <3>;

			r_rsb_pins: rsb@0 {
				pins = "PL0", "PL1";
				function = "s_rsb";
			};
			
			r_pwm_pins: pwm {
				pins = "PL10";
				function = "s_pwm";
			};

			r_i2c_pins_a: i2c-a {
				pins = "PL8", "PL9";
				function = "s_i2c";
			};
		};

		r_rsb: rsb@1f03400 {
			compatible = "allwinner,sun8i-a23-rsb";
			reg = <0x01f03400 0x400>;
			interrupts = <GIC_SPI 39 IRQ_TYPE_LEVEL_HIGH>;
			clocks = <&r_ccu 6>;
			clock-frequency = <3000000>;
			resets = <&r_ccu 2>;
			pinctrl-names = "default";
			pinctrl-0 = <&r_rsb_pins>;
			status = "disabled";
			#address-cells = <1>;
			#size-cells = <0>;
		};
		
		wdt: watchdog@01c20ca0 {
			compatible = "allwinner,sun6i-a31-wdt";
			reg = <0x01c20ca0 0x20>;
			interrupts = <GIC_SPI 25 IRQ_TYPE_LEVEL_HIGH>;
		};
		
	};

	reg_vcc3v3: vcc3v3 {
		compatible = "regulator-fixed";
		regulator-name = "vcc3v3";
		regulator-min-microvolt = <3300000>;
		regulator-max-microvolt = <3300000>;
	};
	
	wiegand_green_led {
		compatible = "gpio-keys";
		#address-cells = <1>;
		#size-cells = <0>;
		pinctrl-names = "default";
		pinctrl-0 = <&wiegand_input_0>;
		status = "ok";

		Wiegand_Green_Led {
			label = "Wiegand Green LED";
			linux,code = <2>;
			gpios = <&pio 6 2 0>;
		};
	};

	wiegand_red_led {
		compatible = "gpio-keys";
		pinctrl-names = "default";
		pinctrl-0 = <&wiegand_input_1>;

		Wiegand_Red_Led {
			label = "Wiegand Red LED";
			linux,code = <3>;
			gpios = <&pio 6 3 0>;
		};
	};

	wiegand_buzzer {
		compatible = "gpio-keys";
		pinctrl-names = "default";
		pinctrl-0 = <&wiegand_input_2>;

		Wiegand_Buzzer {
			label = "Wiegand Buzzer";
			linux,code = <4>;
			gpios = <&pio 6 4 0>;
		};
	};

	wiegand_hld {
		compatible = "gpio-keys";
		pinctrl-names = "default";
		pinctrl-0 = <&wiegand_input_3>;

		Wiegand_Hld {
			label = "Wiegand Hld";
			linux,code = <5>;
			gpios = <&pio 6 5 0>;
		};
	};
	
	anti_tamper {
		compatible = "gpio-keys";
		pinctrl-names = "default";
		pinctrl-0 = <&anti_tamper_input>;

		Anti-Tamper {
			label = "Anti-Tamper";
			linux,code = <7>;
			gpios = <&pio 7 9 0>;
		};
	};	
	
	wiegand_tamper {
		compatible = "gpio-keys";
		pinctrl-names = "default";
		pinctrl-0 = <&wiegand_tamper_input>;
		
		Wiegand-Tamper {
			label = "Wiegand Tamper";
			linux,code = <6>;
			gpios = <&pio 7 0 0>;
		};
	};
	
	factory_default {
	  compatible = "gpio-keys";
	  pinctrl-names = "default";
	  pinctrl-0 = <&factory_default_input>;

	  Factory-Default {
	  	label = "Factory Default";
	  	linux,code = <8>;
	  	gpios = <&pio 7 6 0>;
		};	  
	};

	uc_event_irq {
	  compatible = "gpio-keys";
	  pinctrl-names = "default";
	  pinctrl-0 = <&uc_event_irq>;

	  uc_event {
	  	label = "Uc_Irq";
	  	linux,code = <9>;
	  	gpios = <&pio 1 3 0>;
		};	  
	};
	
	gpio_leds {
		compatible = "gpio-leds";
		
		heartbeat_led {
			label = "heartbeat_led";
			gpios = <&pio 1 5 1>;
			default-state = "off";
			linux,default-trigger = "heartbeat";
		};
		
		cpu_led {
			label = "cpu_led";
			gpios = <&pio 1 6 1>;
			default-state = "off";
			linux,default-trigger = "cpu";
		};
		
		relay {
			label = "relay";
			gpios = <&pio 7 7 0>;
			default-state = "off";
		};
		
		Wiegand_Green_Led {
			label = "Wiegand_Green_Led";
			gpios = <&pio 6 10 0>;
			default-state = "off";
		};
		
		Wiegand_Red_Led {
			label = "Wiegand_Red_Led";
			gpios = <&pio 6 11 0>;
			default-state = "off";
		};
	
		Wiegand_Buzzer {
			label = "Wiegand_Buzzer";
			gpios = <&pio 6 12 0>;
			default-state = "off";
		};
		
 		Wiegand_Hld {
			label = "Wiegand_Hld";
			gpios = <&pio 6 13 0>;
			default-state = "off";
		};		
		
		unused_gpio_01 {
			label = "unused_gpio_1";
			gpios = <&pio 1 2 0>; /*PB2*/
			default-state = "off";
		};
		
		unused_gpio_02 {
			label = "unused_gpio_2";
			gpios = <&pio 1 4 0>; /*PB4*/
			default-state = "off";
		};
		
		unused_gpio_03 {
			label = "unused_gpio_3";
			gpios = <&pio 1 7 0>; /*PB7*/
			default-state = "off";
		};
		
		unused_gpio_04 {
			label = "unused_gpio_4";
			gpios = <&pio 2 0 0>; /*PC0*/
			default-state = "off";
		};
		
		unused_gpio_05 {
			label = "unused_gpio_5";
			gpios = <&pio 2 2 0>; /*PC2*/
			default-state = "off";
		};
		
		unused_gpio_06 {
			label = "unused_gpio_6";
			gpios = <&pio 2 3 0>; /*PC3*/
			default-state = "off";
		};
		
		unused_gpio_07 {
			label = "unused_gpio_7";
			gpios = <&pio 2 4 0>; /*PC4*/
			default-state = "off";
		};
		
		unused_gpio_08 {
			label = "unused_gpio_8";
			gpios = <&pio 2 7 0>; /*PC7*/
			default-state = "off";
		};
		
		unused_gpio_09 {
			label = "unused_gpio_9";
			gpios = <&pio 3 0 0>; /*PD0*/
			default-state = "off";
		};
		
		unused_gpio_10 {
			label = "unused_gpio_10";
			gpios = <&pio 3 1 0>; /*PD1*/
			default-state = "off";
		};
		
		unused_gpio_11 {
			label = "unused_gpio_11";
			gpios = <&pio 3 2 0>; /*PD2*/
			default-state = "off";
		};
		
		unused_gpio_12 {
			label = "unused_gpio_12";
			gpios = <&pio 3 3 0>; /*PD3*/
			default-state = "off";
		};
		
		unused_gpio_13 {
			label = "unused_gpio_13";
			gpios = <&pio 3 4 0>; /*PD4*/
			default-state = "off";
		};
		
		unused_gpio_14 {
			label = "unused_gpio_14";
			gpios = <&pio 3 5 0>; /*PD5*/
			default-state = "off";
		};
		
		unused_gpio_15 {
			label = "unused_gpio_15";
			gpios = <&pio 3 6 0>; /*PD6*/
			default-state = "off";
		};
		
		unused_gpio_16 {
			label = "unused_gpio_16";
			gpios = <&pio 3 7 0>; /*PD7*/
			default-state = "off";
		};
		
		unused_gpio_17 {
			label = "unused_gpio_17";
			gpios = <&pio 3 8 0>; /*PD8*/
			default-state = "off";
		};
		
		unused_gpio_18 {
			label = "unused_gpio_18";
			gpios = <&pio 3 9 0>; /*PD9*/
			default-state = "off";
		};
		
		unused_gpio_19 {
			label = "unused_gpio_19";
			gpios = <&pio 3 12 0>; /*PD12*/
			default-state = "off";
		};
		
		unused_gpio_20 {
			label = "unused_gpio_20";
			gpios = <&pio 3 15 0>; /*PD15*/
			default-state = "off";
		};
		
		unused_gpio_21 {
			label = "unused_gpio_21";
			gpios = <&pio 3 16 0>; /*PD16*/
			default-state = "off";
		};
		
		/*DO NOTE ENABLE LED 22 - MDIO CLK LINES ARE LINKED ON BOARD*/
/*		unused_gpio_22 {
			label = "unused_gpio_22";
			gpios = <&pio 3 19 0>; /*PD19*/
/*			default-state = "off";
		};*/
		
		unused_gpio_23 {
			label = "unused_gpio_23";
			gpios = <&pio 4 1 0>; /*PE1*/
			default-state = "off";
		};
		
		unused_gpio_24 {
			label = "unused_gpio_24";
			gpios = <&pio 4 14 0>; /*PE14*/
			default-state = "off";
		};
		
		unused_gpio_25 {
			label = "unused_gpio_25";
			gpios = <&pio 4 15 0>; /*PE15*/
			default-state = "off";
		};
		
		unused_gpio_26 {
			label = "unused_gpio_26";
			gpios = <&pio 4 16 0>; /*PE16*/
			default-state = "off";
		};
		
		unused_gpio_27 {
			label = "unused_gpio_27";
			gpios = <&pio 4 17 0>; /*PE17*/
			default-state = "off";
		};
		
		unused_gpio_28 {
			label = "unused_gpio_28";
			gpios = <&pio 5 0 0>; /*PF0*/
			default-state = "off";
		};
		
		unused_gpio_29 {
			label = "unused_gpio_29";
			gpios = <&pio 5 1 0>; /*PF1*/
			default-state = "off";
		};
		
		unused_gpio_30 {
			label = "unused_gpio_30";
			gpios = <&pio 5 2 0>; /*PF2*/
			default-state = "off";
		};
		
		unused_gpio_31 {
			label = "unused_gpio_31";
			gpios = <&pio 5 3 0>; /*PF3*/
			default-state = "off";
		};
		
		unused_gpio_32 {
			label = "unused_gpio_32";
			gpios = <&pio 5 4 0>; /*PF4*/
			default-state = "off";
		};
		
		unused_gpio_33 {
			label = "unused_gpio_33";
			gpios = <&pio 5 5 0>; /*PF5*/
			default-state = "off";
		};
		
		unused_gpio_34 {
			label = "unused_gpio_34";
			gpios = <&pio 5 6 0>; /*PF6*/
			default-state = "off";
		};
		
		unused_gpio_35 {
			label = "unused_gpio_35";
			gpios = <&pio 7 10 0>; /*PH10*/
			default-state = "off";
		};
		
		unused_gpio_36 {
			label = "unused_gpio_36";
			gpios = <&r_pio 0 3 0>; /*PL3*/
			default-state = "off";
		};
		
		unused_gpio_37 {
			label = "unused_gpio_37";
			gpios = <&r_pio 0 4 0>; /*PL4*/
			default-state = "off";
		};
		
		unused_gpio_38 {
			label = "unused_gpio_38";
			gpios = <&r_pio 0 5 0>; /*PL5*/
			default-state = "off";
		};
		
		unused_gpio_39 {
			label = "unused_gpio_39";
			gpios = <&r_pio 0 6 0>; /*PL6*/
			default-state = "off";
		};

		unused_gpio_40 {
			label = "unused_gpio_40";
			gpios = <&r_pio 0 7 0>; /*PL7*/
			default-state = "off";
		};

		unused_gpio_41 {
			label = "unused_gpio_41";
			gpios = <&r_pio 0 8 0>; /*PL8*/
			default-state = "off";
		};

		unused_gpio_42 {
			label = "unused_gpio_42";
			gpios = <&r_pio 0 9 0>; /*PL9*/
			default-state = "off";
		};

		unused_gpio_43 {
			label = "unused_gpio_43";
			gpios = <&r_pio 0 11 0>; /*PL11*/
			default-state = "off";
		};

		unused_gpio_44 {
			label = "unused_gpio_44";
			gpios = <&r_pio 0 12 0>; /*PL12*/
			default-state = "off";
			};
	};

	phy_reset_pins: phy_reset_pins {
		pins = "PD24";
		function = "emac";
	};

	beeper {
		compatible = "pwm-beeper";
		pinctrl-names = "default";
		pinctrl-0 = <&r_pwm_pins>;
		pwms = <&r_pwm 0 4000 0>;
	};
	
};

&mmc0 {
	pinctrl-names = "default";
	pinctrl-0 = <&mmc0_pins>;
	vmmc-supply = <&reg_vcc3v3>;
	non-removable;
	disable-wp;
	bus-width = <4>;
	status = "okay";
};

&r_rsb {
	status = "okay";

	axp803: pmic@3a3 {
		compatible = "x-powers,axp803";
		reg = <0x3a3>;
		interrupt-parent = <&r_intc>;
		interrupts = <0 IRQ_TYPE_LEVEL_LOW>;
	};
};

#include "axp803.dtsi"

&reg_aldo2 {
	regulator-always-on;
	regulator-min-microvolt = <1800000>;
	regulator-max-microvolt = <3300000>;
	regulator-name = "vcc-pl";
};

&ac_power_supply {
	status = "okay";
	};

&battery_power_supply {
	status = "okay";
};

&tcon1 {
	status = "okay";
};

&de {
	status = "okay";
};

&reg_aldo3 {
	regulator-always-on;
	regulator-min-microvolt = <3000000>;
	regulator-max-microvolt = <3000000>;
	regulator-name = "vcc-pll-avcc";
};

&reg_dcdc1 {
	regulator-always-on;
	regulator-min-microvolt = <3300000>;
	regulator-max-microvolt = <3300000>;
	regulator-name = "vcc-3v3";
};

&reg_dcdc2 {
	regulator-always-on;
	regulator-min-microvolt = <1040000>;
	regulator-max-microvolt = <1300000>;
	regulator-name = "vdd-cpux";
};

/* DCDC3 is polyphased with DCDC2 */

&reg_dcdc5 {
	regulator-always-on;
	regulator-min-microvolt = <1200000>;
	regulator-max-microvolt = <1200000>;
	regulator-name = "vcc-dram";
};

&reg_dcdc6 {
	regulator-always-on;
	regulator-min-microvolt = <1100000>;
	regulator-max-microvolt = <1100000>;
	regulator-name = "vdd-sys";
};

&reg_eldo1 {
	regulator-always-on;
	regulator-min-microvolt = <1800000>;
	regulator-max-microvolt = <1800000>;
	regulator-name = "vdd-1v8-lpddr";
};

&reg_fldo1 {
	regulator-min-microvolt = <1200000>;
	regulator-max-microvolt = <1200000>;
	regulator-name = "vcc-1v2-hsic";
};

/*
 * The A64 chip cannot work without this regulator off, although
 * it seems to be only driving the AR100 core.
 * Maybe we don't still know well about CPUs domain.
 */
&reg_fldo2 {
	regulator-always-on;
	regulator-min-microvolt = <1100000>;
	regulator-max-microvolt = <1100000>;
	regulator-name = "vdd-cpus";
};

&reg_rtc_ldo {
	regulator-name = "vcc-rtc";
};

&de {
	status = "okay";
};

&ehci0 {
	status = "okay";
};

&ehci1 {
	status = "okay";
};

&mmc2 {
	pinctrl-names = "default";
	pinctrl-0 = <&mmc2_pins>;
	vmmc-supply = <&reg_vcc3v3>;
	vqmmc-supply = <&reg_vcc1v8>;
	bus-width = <8>;
	non-removable;
	cap-mmc-hw-reset;
	status = "okay";
};

&ohci0 {
	status = "okay";
};

&ohci1 {
	status = "okay";
};

&reg_dc1sw {
	regulator-name = "vcc-phy";
};

&reg_dldo1 {
	regulator-min-microvolt = <3300000>;
	regulator-max-microvolt = <3300000>;
	regulator-name = "vcc-hdmi";
};

&reg_dldo2 {
	regulator-min-microvolt = <3300000>;
	regulator-max-microvolt = <3300000>;
	regulator-name = "vcc-mipi";
};

&reg_dldo4 {
	regulator-min-microvolt = <3300000>;
	regulator-max-microvolt = <3300000>;
	regulator-name = "vcc-wifi";
};

&uart0 {
	pinctrl-names = "default";
	pinctrl-0 = <&uart0_pins_a>;
	status = "okay";
};

&usb_otg {
	dr_mode = "host";
	status = "okay";
};

&emac {
	pinctrl-names = "default";
	pinctrl-0 = <&rmii_pins>;
	phy-mode = "rmii";
	phy-handle = <&ext_rmii_phy>;
	phy-supply = <&reg_dc1sw>;
	snps,reset-gpios = <&phy_reset_pins>;
	snps,reset-active-low = <1>;
	snps,reset-delay-us = <200>;
	status = "okay";
};

&mdio {
	ext_rmii_phy: ethernet-phy@0 {
		compatible = "ethernet-phy-ieee802.3-c22";
		reg = <0>;
	};
};

&usbphy {
	status = "okay";
};

